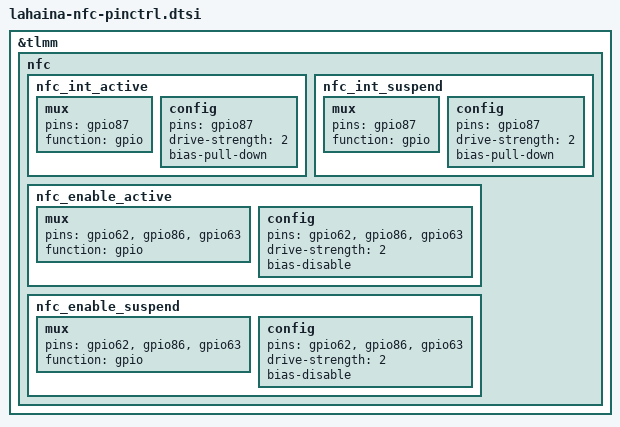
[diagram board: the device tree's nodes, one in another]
// SPDX-License-Identifier: BSD-3-Clause
/*
 * Copyright (c) Qualcomm Technologies, Inc. and/or its subsidiaries.
 */

&tlmm {
	nfc {
		nfc_int_active: nfc_int_active {
			/* active state */
			mux {
				/* NFC Read Interrupt */
				pins = "gpio87";
				function = "gpio";
			};

			config {
				pins = "gpio87";
				drive-strength = <2>; /* 2 MA */
				bias-pull-down;
			};
		};

		nfc_int_suspend: nfc_int_suspend {
			/* sleep state */
			mux {
				/* NFC Read Interrupt */
				pins = "gpio87";
				function = "gpio";
			};

			config {
				pins = "gpio87";
				drive-strength = <2>; /* 2 MA */
				bias-pull-down;
			};
		};

		nfc_enable_active: nfc_enable_active {
			mux {
				/* Enable, Firmware and Clock request gpios */
				pins = "gpio62","gpio86", "gpio63";
				function = "gpio";
			};

			config {
				pins = "gpio62", "gpio86", "gpio63";
				drive-strength = <2>; /* 2 MA */
				bias-disable;
			};
		};

		nfc_enable_suspend: nfc_enable_suspend {
			mux {
				pins = "gpio62", "gpio86", "gpio63";
				function = "gpio";
			};

			config {
				pins = "gpio62", "gpio86", "gpio63";
				drive-strength = <2>; /* 2 MA */
				bias-disable;
			};
		};
	}; //nfc
}; //tlmm

